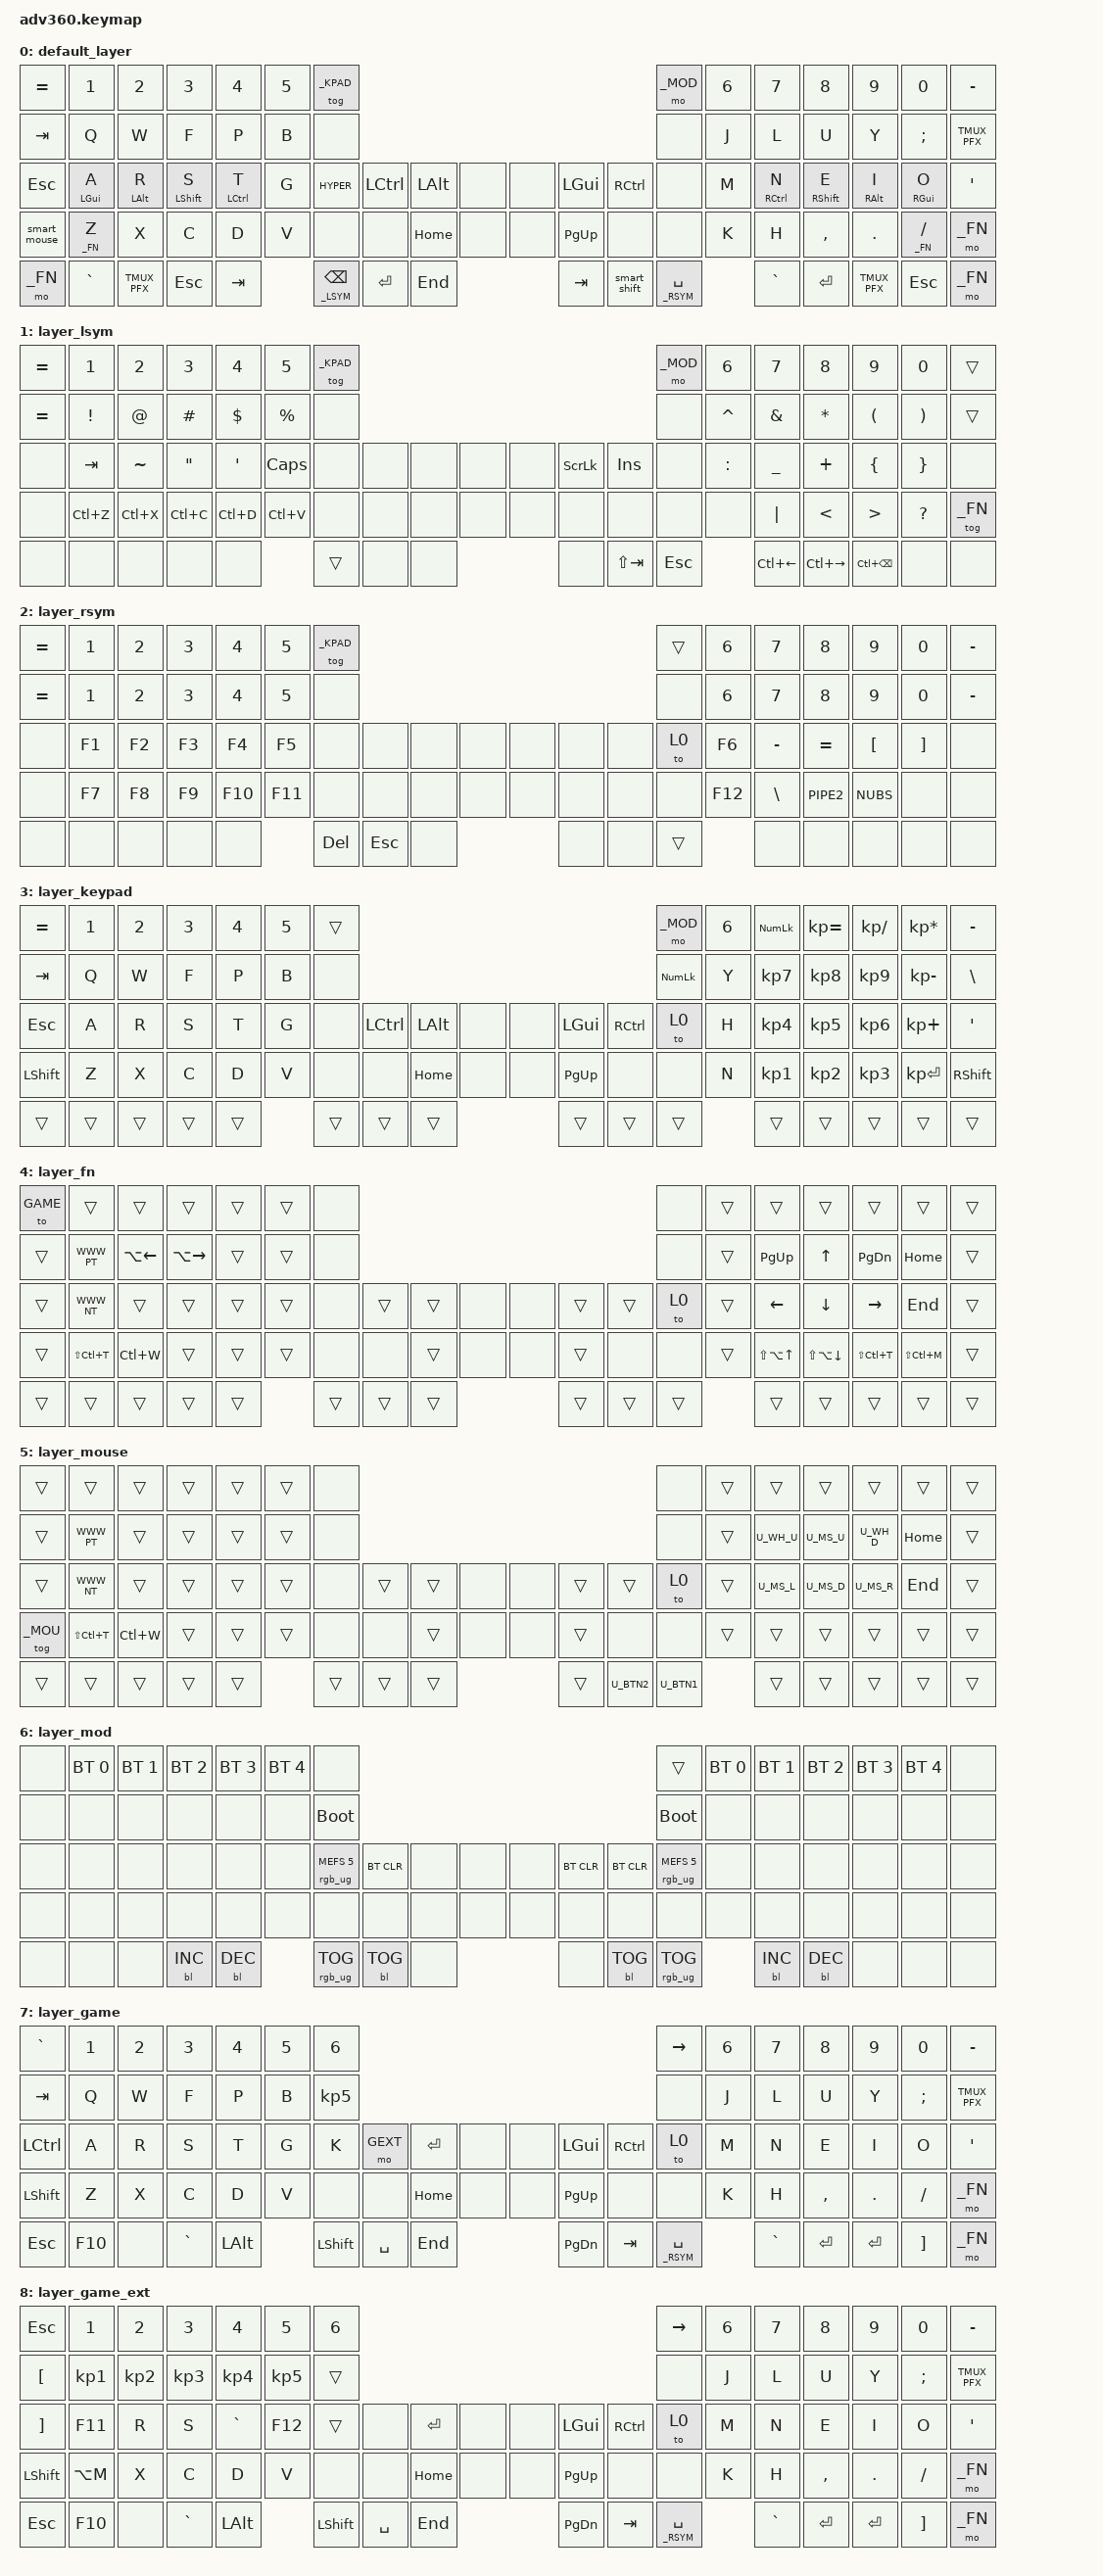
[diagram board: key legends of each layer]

/*
 * Copyright (c) 2020 The ZMK Contributors
 *
 * SPDX-License-Identifier: MIT
 */


/* THIS FILE WAS GENERATED!
 *
 * This file was generated automatically. You may or may not want to
 * edit it directly.
 */

#include <behaviors.dtsi>
#include <dt-bindings/zmk/keys.h>
#include <dt-bindings/zmk/bt.h>
#include <dt-bindings/zmk/rgb.h>
#include <dt-bindings/zmk/backlight.h>
#include "./helper.h"

#define DEFAULT 0
#define _LSYM   1
#define _RSYM   2
#define _KPAD   3
#define _FN     4
#define _MOU    5
#define _MOD    6
#define GAME    7
#define GEXT    8

#define HYPER      LS(LC(LA(LGUI)))
#define HPR(X)     LS(LC(LA(LG(X))))
#define WWW_PT     LC(PG_UP)
#define WWW_NT     LC(PG_DN)
#define TMUX_PFX   LC(A)
#define LHS_KEYS   0 1 2 3 4 5 6 14 15 16 17 18 19 20 28 29 30 31 32 33 34 48 49 50 51 52 53 68 69 70 71 72
#define RHS_KEYS   7 8 9 10 11 12 13 21 22 23 24 25 26 27 41 42 43 44 45 46 47 58 63 64 65 66 67 79 80 81 82 83
#define LHS_THUMBS 35 36 37 54 55 56 57 73 74 75 
#define RHS_THUMBS 38 39 40 59 60 61 62 76 77 78 
#define CENT       &mt LCTRL ENTER
#define RSYM       &lt_rp _RSYM SPACE
#define LSYM       &lt_rp_hp _LSYM BSPC

// total of 84 keys
// 0   1   2   3   4   5   6                            7   8   9   10  11   12   13
// 14  15  16  17  18  19  20                           21  22  23  24  25   26   27
// 28  29  30  31  32  33  34  35  36  37   38  39  40  41  42  43  44  45   46   47
// 48  49  50  51  52  53  54  55  56  57   58  59  60  61  62  63  64  65   66   67
// 68  69  70  71  72      73  74  75           76  77  78      79  80  81   82   83
//

#define LT4 15
#define LT3 16
#define LT2 17
#define LT1 18
#define LT0 19
#define LM4 29
#define LM3 30
#define LM2 31
#define LM1 32
#define LM0 33
#define LB4 48
#define LB3 49
#define LB2 50
#define LB1 51
#define LB0 52
#define LH2 73
#define LH1 74
#define LH0 75

#define RT4 26
#define RT3 25
#define RT2 24
#define RT1 23
#define RT0 22
#define RM4 46
#define RM3 45
#define RM2 44
#define RM1 43
#define RM0 42
#define RB4 66
#define RB3 65
#define RB2 64
#define RB1 63
#define RB0 62
#define RH2 78
#define RH1 77
#define RH0 76

// &kp EQUAL      &kp N1         &kp N2         &kp N3           &kp N4        &kp N5    &tog _KPAD                                                                          &mo _MOD              &kp N6       &kp N7       &kp N8         &kp N9         &kp N0         &kp MINUS
// &kp TAB        &kp Q          &kp W          &kp F            &kp P         &kp B     &none                                                                               &none                 &kp J        &kp L        &kp U          &kp Y          &kp SEMICOLON  &kp TMUX_PFX
// &kp ESC        &hm LGUI A     &hm LALT R     &hm LSHFT S      &hm LCTRL T   &kp G     &kp HYPER              &kp LCTRL  &kp LALT   &none   &none  &kp LGUI   &kp RCTRL    &none                 &kp M        &hm RCTRL N  &hm RSHFT E    &hm RALT I     &hm RGUI O     &kp SQT
// &mo _FN        &lt_rp _FN Z   &kp X          &kp C            &kp D         &kp V     &none                  &none      &kp HOME   &none   &none  &kp PG_UP  &none        &none                 &kp K        &kp H        &kp COMMA      &kp DOT        &lt_rp _FN FSLH   &mo _FN
// &mo _FN        &kp GRAVE      &kp LC(A)      &kp ESC          &kp ESC                 &lt_rp_hp _LSYM BSPC   &kp ENTER  &kp END                   &kp PG_DN  &kp TAB      &lt_rp _RSYM SPACE                 &kp GRAVE    &kp ENTER      &none          &kp RBKT       &mo _FN
 
&sl {
    release-after-ms = <400>;
};

&caps_word {  // mods deactivate caps-word, requires PR #1441
    /delete-property/ ignore-modifiers;
};

&num_word {
	layers = <_RSYM>;
};

/ {
    behaviors {
      skq: sticky_key_quick_release {
        compatible = "zmk,behavior-sticky-key";
        label = "STICKY_KEY_QUICK_RELEASE";
        #binding-cells = <1>;
        bindings = <&kp>;
        release-after-ms = <1000>;
        quick-release;
        ignore-modifiers;
      };
    };
};

#define SMART_NUM &smart_num _RSYM 0

#include "mouse.dtsi"
#include "combos.dtsi"
/ {
  behaviors {
    #include "macros.dtsi"

	// tap: num-word
	// hold: kpad layer
	// double tap: stick kpad layer
	smart_num: smart_num {
		compatible = "zmk,behavior-hold-tap";
        flavor = "balanced";
		label = "SMART_NUM";
		#binding-cells = <2>;
		tapping-term-ms = <200>;
		quick-tap-ms = <180>;
		bindings = <&mo>, <&num_dance>;
	};

	num_dance: num_dance {
		compatible = "zmk,behavior-tap-dance";
		label = "NUM_DANCE";
		#binding-cells = <0>;
		tapping-term-ms = <200>;
		bindings = <&num_word>, <&sl _KPAD>;
	};

	smart_shift: smart_shift {
		compatible = "zmk,behavior-mod-morph";
		label = "SMART_SHIFT";
        #binding-cells = <0>;
        bindings = <&skq LSHIFT>, <&caps_word>;
		mods = <(MOD_LSFT)>;
	};

    hm_l: homerow_mods_left {
        compatible = "zmk,behavior-hold-tap";
        label = "HOMEROW_MODS_LEFT";
        #binding-cells = <2>;
        bindings = <&kp>, <&kp>;
        tapping-term-ms = <200>;
        quick-tap-ms = <180>;
        global-quick-tap-ms = <130>;
        flavor = "balanced";
        hold-trigger-key-positions = <RHS_KEYS RHS_THUMBS>;
		hold-trigger-on-release;
    };
    hm_r: homerow_mods_right {
        compatible = "zmk,behavior-hold-tap";
        label = "HOMEROW_MODS_RIGHT";
        #binding-cells = <2>;
        bindings = <&kp>, <&kp>;
        tapping-term-ms = <200>;
        quick-tap-ms = <180>;
        global-quick-tap-ms = <130>;
        flavor = "balanced";
        hold-trigger-key-positions = <LHS_KEYS LHS_THUMBS>;
		hold-trigger-on-release;
    };
    lt_rp: lt_repeat {
        compatible = "zmk,behavior-hold-tap";
        label = "LT_REPEAT";
        #binding-cells = <2>;
        tapping-term-ms = <130>;
        quick_tap_ms = <180>;
        flavor = "balanced";
        bindings = <&mo>, <&kp>;
    };
    lt_rp_hp: lt_repeat_holdpreferred {
        compatible = "zmk,behavior-hold-tap";
        label = "LT_REPEAT_HOLD_PREFERRED";
        #binding-cells = <2>;
        tapping-term-ms = <150>;
        quick_tap_ms = <200>;
        flavor = "hold-preferred";
        bindings = <&mo>, <&kp>;
    };
  };

	keymap {
		compatible = "zmk,keymap";

		default_layer {
			bindings = <
				&kp EQUAL      &kp N1         &kp N2         &kp N3           &kp N4        &kp N5    &tog _KPAD                                                                  &mo _MOD  &kp N6       &kp N7         &kp N8         &kp N9         &kp N0           &kp MINUS
				&kp TAB        &kp Q          &kp W          &kp F            &kp P         &kp B     &none                                                                       &none     &kp J        &kp L          &kp U          &kp Y          &kp SEMICOLON    &kp TMUX_PFX
				&kp ESC        &hm_l LGUI A   &hm_l LALT R   &hm_l LSHFT S    &hm_l LCTRL T &kp G     &kp HYPER    &kp LCTRL  &kp LALT   &none   &none  &kp LGUI   &kp RCTRL      &none     &kp M        &hm_r RCTRL N  &hm_r RSHFT E  &hm_r RALT I   &hm_r RGUI O     &kp SQT
				&smart_mouse   &lt_rp _FN Z   &kp X          &kp C            &kp D         &kp V     &none        &none      &kp HOME   &none   &none  &kp PG_UP  &none          &none     &kp K        &kp H          &kp COMMA      &kp DOT        &lt_rp _FN FSLH  &mo _FN
				&mo _FN        &kp GRAVE      &kp TMUX_PFX   &kp ESC          &kp TAB                 LSYM         &kp ENTER  &kp END                   &kp TAB    &smart_shift   RSYM                   &kp GRAVE      &kp ENTER      &kp TMUX_PFX   &kp ESC          &mo _FN
			>;
		};

        layer_lsym {
            bindings = <
				&kp EQUAL     &kp N1        &kp N2        &kp N3        &kp N4        &kp N5        &tog _KPAD                                                         &mo _MOD      &kp N6      &kp N7       &kp N8          &kp N9                &kp N0       &trans
				&kp EQUAL     &kp EXCL      &kp AT        &kp HASH      &kp DLLR      &kp PRCNT     &none                                                              &none         &kp CARET   &kp AMPS     &kp ASTRK       &kp LPAR              &kp RPAR     &trans
				&none         &kp TAB       &kp TILDE     &kp DQT       &kp SQT       &kp CAPS      &none       &none  &none   &none   &none  &kp SLCK   &kp INS       &none         &kp COLON   &kp UNDER    &kp PLUS        &kp LBRC              &kp RBRC     &none
				&none         &kp LC(Z)     &kp LC(X)     &kp LC(C)     &kp LC(D)     &kp LC(V)     &none       &none  &none   &none   &none  &none      &none         &none         &none       &kp PIPE     &kp LESS_THAN   &kp GREATER_THAN      &kp QMARK    &tog _FN
				&none         &none         &none         &none         &none                       &trans      &none  &none                  &none      &kp LS(TAB)   &kp ESC                   &kp LC(LEFT) &kp LC(RIGHT)   &kp LC(BSPC)          &none        &none
            >;
        };

        layer_rsym {
            bindings = <
				&kp EQUAL     &kp N1        &kp N2    &kp N3     &kp N4       &kp N5     &tog _KPAD                                                   &trans      &kp N6         &kp N7     &kp N8        &kp N9        &kp N0    &kp MINUS
				&kp EQUAL     &kp N1        &kp N2    &kp N3     &kp N4       &kp N5     &none                                                        &none       &kp N6         &kp N7     &kp N8        &kp N9        &kp N0    &kp MINUS
				&none         &kp F1        &kp F2    &kp F3     &kp F4       &kp F5     &none         &none    &none   &none   &none  &none  &none   &to 0       &kp F6         &kp MINUS  &kp EQUAL     &kp LBKT      &kp RBKT  &none
				&none         &kp F7        &kp F8    &kp F9     &kp F10      &kp F11    &none         &none    &none   &none   &none  &none  &none   &none       &kp F12        &kp BSLH   &kp PIPE2     &kp NUBS      &none     &none
				&none         &none         &none     &none      &none                   &kp DEL       &kp ESC  &none                  &none  &none   &trans                     &none      &none         &none         &none     &none
            >;
        };

		layer_keypad {
            bindings = <
				&kp EQUAL      &kp N1     &kp N2    &kp N3     &kp N4        &kp N5     &trans                                                               &mo _MOD   &kp N6      &kp KP_NUM    &kp KP_EQUAL   &kp KP_DIVIDE  &kp KP_MULTIPLY  &kp MINUS
				&kp TAB        &kp Q      &kp W     &kp F      &kp P         &kp B      &none                                                                &kp KP_NUM &kp Y       &kp KP_N7     &kp KP_N8      &kp KP_N9      &kp KP_MINUS     &kp BSLH
				&kp ESC        &kp A      &kp R     &kp S      &kp T         &kp G      &none     &kp LCTRL  &kp LALT   &none   &none   &kp LGUI  &kp RCTRL  &to 0      &kp H       &kp KP_N4     &kp KP_N5      &kp KP_N6      &kp KP_PLUS      &kp SQT
				&kp LSHFT      &kp Z      &kp X     &kp C      &kp D         &kp V      &none     &none      &kp HOME   &none   &none   &kp PG_UP &none      &none      &kp N       &kp KP_N1     &kp KP_N2      &kp KP_N3      &kp KP_ENTER     &kp RSHFT
				&trans         &trans     &trans    &trans     &trans                   &trans    &trans     &trans                    &trans     &trans     &trans                 &trans        &trans         &trans         &trans           &trans
            >;
        };

        layer_fn {
            bindings = <
				&to GAME &trans         &trans        &trans         &trans  &trans    &none                                                   &none    &trans    &trans          &trans            &trans          &trans          &trans
				&trans   &kp WWW_PT     &kp LA(LEFT)  &kp LA(RIGHT)  &trans  &trans    &none                                                   &none    &trans    &kp PG_UP       &kp UP            &kp PG_DN       &kp HOME        &trans
				&trans   &kp WWW_NT     &trans        &trans         &trans  &trans    &none   &trans  &trans   &none   &none  &trans  &trans  &to 0    &trans    &kp LEFT        &kp DOWN          &kp RIGHT       &kp END         &trans
				&trans   &kp LS(LC(T))  &kp LC(W)     &trans         &trans  &trans    &none   &none   &trans   &none   &none  &trans  &none   &none    &trans    &kp LS(LA(UP))  &kp LS(LA(DOWN))  &kp LS(LC(T))   &kp LS(LC(M))   &trans
				&trans   &trans         &trans        &trans         &trans            &trans  &trans  &trans                  &trans  &trans  &trans             &trans          &trans            &trans          &trans          &trans
            >;
        };

        layer_mouse {
            bindings = <
				&trans      &trans         &trans     &trans  &trans  &trans    &none                                                     &none  &trans  &trans    &trans   &trans   &trans   &trans
				&trans      &kp WWW_PT     &trans     &trans  &trans  &trans    &none                                                     &none  &trans  U_WH_U    U_MS_U   U_WH_D   &kp HOME &trans
				&trans      &kp WWW_NT     &trans     &trans  &trans  &trans    &none     &trans  &trans   &none   &none  &trans  &trans  &to 0  &trans  U_MS_L    U_MS_D   U_MS_R   &kp END  &trans
				&tog _MOU   &kp LS(LC(T))  &kp LC(W)  &trans  &trans  &trans    &none     &none   &trans   &none   &none  &trans   &none  &none  &trans  &trans    &trans   &trans   &trans   &trans
				&trans      &trans         &trans     &trans  &trans            &trans    &trans  &trans                  &trans  U_BTN2  U_BTN1         &trans    &trans   &trans   &trans   &trans
            >;
        };

        layer_mod {
            bindings = <
  &none  &bt BT_SEL 0  &bt BT_SEL 1  &bt BT_SEL 2  &bt BT_SEL 3  &bt BT_SEL 4                             &none                                                                              &trans  &bt BT_SEL 0  &bt BT_SEL 1  &bt BT_SEL 2  &bt BT_SEL 3  &bt BT_SEL 4   &none
  &none         &none         &none         &none         &none         &none                       &bootloader                                                                         &bootloader         &none         &none         &none         &none         &none   &none
  &none         &none         &none         &none         &none         &none            &rgb_ug RGB_MEFS_CMD 5  &bt BT_CLR   &none   &none   &none  &bt BT_CLR  &bt BT_CLR  &rgb_ug RGB_MEFS_CMD 5         &none         &none         &none         &none         &none   &none
  &none         &none         &none         &none         &none         &none                             &none       &none   &none   &none   &none       &none       &none                   &none         &none         &none         &none         &none         &none   &none
  &none         &none         &none    &bl BL_INC    &bl BL_DEC                                 &rgb_ug RGB_TOG  &bl BL_TOG   &none                       &none  &bl BL_TOG         &rgb_ug RGB_TOG                  &bl BL_INC    &bl BL_DEC         &none         &none   &none
            >;
        };
		
		layer_game {
			bindings = <
				&kp GRAVE      &kp N1      &kp N2      &kp N3        &kp N4        &kp N5     &kp N6                                                                   &kp RIGHT   &kp N6               &kp N7       &kp N8         &kp N9     &kp N0          &kp MINUS
				&kp TAB        &kp Q       &kp W       &kp F         &kp P         &kp B      &kp KP_N5                                                                &none       &kp J                &kp L        &kp U          &kp Y      &kp SEMICOLON   &kp TMUX_PFX
				&kp LCTRL      &kp A       &kp R       &kp S         &kp T         &kp G      &kp K      &mo GEXT      &kp ENTER  &none   &none  &kp LGUI   &kp RCTRL  &to 0       &kp M                &kp N        &kp E          &kp I      &kp O           &kp SQT
				&kp LSHFT      &kp Z       &kp X       &kp C         &kp D         &kp V      &none      &none         &kp HOME   &none   &none  &kp PG_UP  &none      &none       &kp K                &kp H        &kp COMMA      &kp DOT    &kp FSLH        &mo _FN
				&kp ESC        &kp F10     &none       &kp GRAVE     &kp LALT      &kp LSHFT  &kp SPACE  &kp END                                            &kp PG_DN  &kp TAB     &lt_rp _RSYM SPACE   &kp GRAVE    &kp ENTER      &kp ENTER  &kp RBKT        &mo _FN
			>;
		};
		layer_game_ext {
			bindings = <
				&kp ESC      &kp N1       &kp N2       &kp N3        &kp N4      &kp N5     &kp N6                                                                   &kp RIGHT   &kp N6     &kp N7       &kp N8         &kp N9       &kp N0          &kp MINUS
				&kp LBKT     &kp KP_N1    &kp KP_N2    &kp KP_N3     &kp KP_N4   &kp KP_N5  &trans                                                                   &none       &kp J      &kp L        &kp U          &kp Y        &kp SEMICOLON   &kp TMUX_PFX
				&kp RBKT     &kp F11      &kp R        &kp S         &kp GRAVE   &kp F12    &trans     &none      &kp ENTER  &none   &none  &kp LGUI   &kp RCTRL     &to 0       &kp M      &kp N        &kp E          &kp I        &kp O           &kp SQT
				&kp LSHFT    &kp LA(M)    &kp X        &kp C         &kp D       &kp V      &none      &none      &kp HOME   &none   &none  &kp PG_UP  &none         &none       &kp K      &kp H        &kp COMMA      &kp DOT      &kp FSLH        &mo _FN
				&kp ESC      &kp F10      &none        &kp GRAVE     &kp LALT               &kp LSHFT  &kp SPACE  &kp END                   &kp PG_DN  &kp TAB       &lt_rp _RSYM SPACE     &kp GRAVE    &kp ENTER      &kp ENTER    &kp RBKT        &mo _FN
			>;
		};

    };
};
